# CY8C5888LTI_LP097 register map
File version: 0.1
Registers are 8-bit, read-write, no defined reset value unless marked. A register's access mark holds for its fields unless they carry their own. Offsets are from the block's base; [hi:lo] are bit positions; 'fields as' and 'values as' point back to an identical list.

## RC_Ch1_Timer
Base 0x00000000
0x40006408 RC_Ch1_Timer_COUNTER 24-bit — UDB.A0 - Current Down Counter Value
0x40006428 RC_Ch1_Timer_PERIOD 24-bit — UDB.D0 - Assigned Period
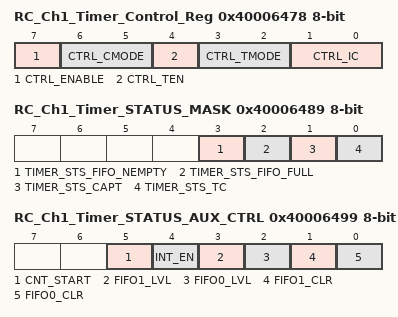
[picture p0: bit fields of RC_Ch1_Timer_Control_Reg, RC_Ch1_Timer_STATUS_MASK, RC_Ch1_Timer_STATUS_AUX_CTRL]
0x40006478 RC_Ch1_Timer_Control_Reg — UDB Control Register - Assigned Control Register Value
  [7] CTRL_ENABLE — Enable the Timer
  [6:5] CTRL_CMODE — Capture Mode
  [4] CTRL_TEN — Trigger Enable Bit
  [3:2] CTRL_TMODE — Trigger Mode
  [1:0] CTRL_IC — Interrupt Count
0x40006489 RC_Ch1_Timer_STATUS_MASK — UDB Status bits Interrupt Mask Enable Register
  [3] TIMER_STS_FIFO_NEMPTY ro — FIFO Empty status
  [2] TIMER_STS_FIFO_FULL ro — FIFO Full Status
  [1] TIMER_STS_CAPT ro — Enables the Interrupt on Capture
  [0] TIMER_STS_TC ro — Enables the Interrupt on TC
0x40006499 RC_Ch1_Timer_STATUS_AUX_CTRL — UDB Auxilliary Control Register
  [5] CNT_START — FIFO0 clear
    0=E_CNT_START0 (Disable counter); 1=E_CNT_START1 (Enable counter)
  [4] INT_EN
    0=E_INT_EN0 (Interrupt disabled); 1=E_INT_EN1 (Interrupt enabled)
  [3] FIFO1_LVL — FIFO level
    0=E_FIFO_LVL_0 (FIFO LVL: input mode: FIFO not full; output mode: FIFO not empty); 1=E_FIFO_LVL_1 (FIFO LVL: input mode: FIFO at least 1/2 empty; output mode: FIFO at least 1/2 full)
  [2] FIFO0_LVL — FIFO level
    values as FIFO1_LVL
  [1] FIFO1_CLR — FIFO1 clear
    0=E_FIFO_CLR_0 (Normal FIFO operation); 1=E_FIFO_CLR_1 (Clear FIFO state)
  [0] FIFO0_CLR — FIFO0 clear
    values as FIFO1_CLR

## Drive_DC_Motor_PWM
Base 0x00000000
0x4000652A Drive_DC_Motor_PWM__COMPARE1 — UDB.D0 - Assigned Compare1 Value
0x4000653A Drive_DC_Motor_PWM__COMPARE2 — UDB.D1 - Assigned Compare2 Value
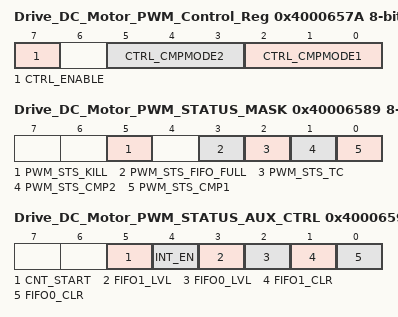
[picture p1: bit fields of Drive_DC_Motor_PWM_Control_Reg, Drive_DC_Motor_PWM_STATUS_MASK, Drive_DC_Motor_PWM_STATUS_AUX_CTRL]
0x4000657A Drive_DC_Motor_PWM_Control_Reg — UDB Control Register - Assigned Control Register Value
  [7] CTRL_ENABLE — Enable the PWM
  [5:3] CTRL_CMPMODE2 — Compare mode 2
  [2:0] CTRL_CMPMODE1 — Compare mode 1
0x40006589 Drive_DC_Motor_PWM_STATUS_MASK — UDB Status bits Interrupt Mask Enable Register
  [5] PWM_STS_KILL ro — Enables the Interrupt on Kill
  [3] PWM_STS_FIFO_FULL ro — FIFO Full Status Mask
  [2] PWM_STS_TC ro — Enables the Interrupt on Terminal Count
  [1] PWM_STS_CMP2 ro — Enables the Interrupt on Compare 2
  [0] PWM_STS_CMP1 ro — Enables the Interrupt on Compare 1
0x4000659A Drive_DC_Motor_PWM_STATUS_AUX_CTRL — UDB Auxilliary Control Register
  [5] CNT_START — FIFO0 clear
    0=E_CNT_START0 (Disable counter); 1=E_CNT_START1 (Enable counter)
  [4] INT_EN
    0=E_INT_EN0 (Interrupt disabled); 1=E_INT_EN1 (Interrupt enabled)
  [3] FIFO1_LVL — FIFO level
    0=E_FIFO_LVL_0 (FIFO LVL: input mode: FIFO not full; output mode: FIFO not empty); 1=E_FIFO_LVL_1 (FIFO LVL: input mode: FIFO at least 1/2 empty; output mode: FIFO at least 1/2 full)
  [2] FIFO0_LVL — FIFO level
    values as FIFO1_LVL
  [1] FIFO1_CLR — FIFO1 clear
    0=E_FIFO_CLR_0 (Normal FIFO operation); 1=E_FIFO_CLR_1 (Clear FIFO state)
  [0] FIFO0_CLR — FIFO0 clear
    values as FIFO1_CLR

## RC_Ch4_Timer
Base 0x00000000
0x40006404 RC_Ch4_Timer_COUNTER 24-bit — UDB.A0 - Current Down Counter Value
0x40006424 RC_Ch4_Timer_PERIOD 24-bit — UDB.D0 - Assigned Period
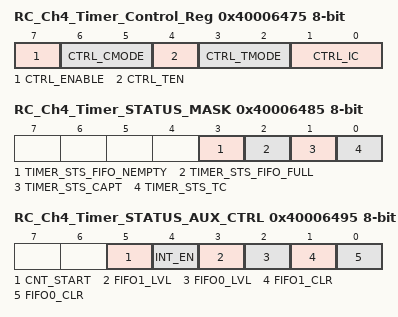
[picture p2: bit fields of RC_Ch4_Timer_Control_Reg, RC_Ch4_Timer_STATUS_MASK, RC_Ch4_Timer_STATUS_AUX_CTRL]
0x40006475 RC_Ch4_Timer_Control_Reg — UDB Control Register - Assigned Control Register Value
  [7] CTRL_ENABLE — Enable the Timer
  [6:5] CTRL_CMODE — Capture Mode
  [4] CTRL_TEN — Trigger Enable Bit
  [3:2] CTRL_TMODE — Trigger Mode
  [1:0] CTRL_IC — Interrupt Count
0x40006485 RC_Ch4_Timer_STATUS_MASK — UDB Status bits Interrupt Mask Enable Register
  [3] TIMER_STS_FIFO_NEMPTY ro — FIFO Empty status
  [2] TIMER_STS_FIFO_FULL ro — FIFO Full Status
  [1] TIMER_STS_CAPT ro — Enables the Interrupt on Capture
  [0] TIMER_STS_TC ro — Enables the Interrupt on TC
0x40006495 RC_Ch4_Timer_STATUS_AUX_CTRL — UDB Auxilliary Control Register
  [5] CNT_START — FIFO0 clear
    0=E_CNT_START0 (Disable counter); 1=E_CNT_START1 (Enable counter)
  [4] INT_EN
    0=E_INT_EN0 (Interrupt disabled); 1=E_INT_EN1 (Interrupt enabled)
  [3] FIFO1_LVL — FIFO level
    0=E_FIFO_LVL_0 (FIFO LVL: input mode: FIFO not full; output mode: FIFO not empty); 1=E_FIFO_LVL_1 (FIFO LVL: input mode: FIFO at least 1/2 empty; output mode: FIFO at least 1/2 full)
  [2] FIFO0_LVL — FIFO level
    values as FIFO1_LVL
  [1] FIFO1_CLR — FIFO1 clear
    0=E_FIFO_CLR_0 (Normal FIFO operation); 1=E_FIFO_CLR_1 (Clear FIFO state)
  [0] FIFO0_CLR — FIFO0 clear
    values as FIFO1_CLR

## RC_Ch3_Timer
Base 0x00000000
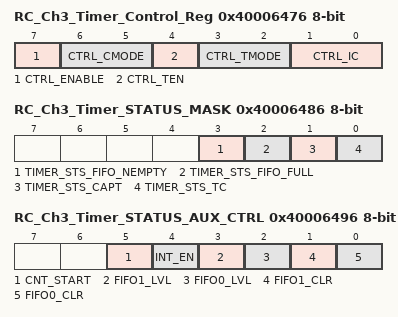
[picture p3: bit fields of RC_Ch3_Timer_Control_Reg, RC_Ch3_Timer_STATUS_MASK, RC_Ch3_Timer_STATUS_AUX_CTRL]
0x40006476 RC_Ch3_Timer_Control_Reg — UDB Control Register - Assigned Control Register Value
  [7] CTRL_ENABLE — Enable the Timer
  [6:5] CTRL_CMODE — Capture Mode
  [4] CTRL_TEN — Trigger Enable Bit
  [3:2] CTRL_TMODE — Trigger Mode
  [1:0] CTRL_IC — Interrupt Count
0x40006486 RC_Ch3_Timer_STATUS_MASK — UDB Status bits Interrupt Mask Enable Register
  [3] TIMER_STS_FIFO_NEMPTY ro — FIFO Empty status
  [2] TIMER_STS_FIFO_FULL ro — FIFO Full Status
  [1] TIMER_STS_CAPT ro — Enables the Interrupt on Capture
  [0] TIMER_STS_TC ro — Enables the Interrupt on TC
0x40006496 RC_Ch3_Timer_STATUS_AUX_CTRL — UDB Auxilliary Control Register
  [5] CNT_START — FIFO0 clear
    0=E_CNT_START0 (Disable counter); 1=E_CNT_START1 (Enable counter)
  [4] INT_EN
    0=E_INT_EN0 (Interrupt disabled); 1=E_INT_EN1 (Interrupt enabled)
  [3] FIFO1_LVL — FIFO level
    0=E_FIFO_LVL_0 (FIFO LVL: input mode: FIFO not full; output mode: FIFO not empty); 1=E_FIFO_LVL_1 (FIFO LVL: input mode: FIFO at least 1/2 empty; output mode: FIFO at least 1/2 full)
  [2] FIFO0_LVL — FIFO level
    values as FIFO1_LVL
  [1] FIFO1_CLR — FIFO1 clear
    0=E_FIFO_CLR_0 (Normal FIFO operation); 1=E_FIFO_CLR_1 (Clear FIFO state)
  [0] FIFO0_CLR — FIFO0 clear
    values as FIFO1_CLR
0x40006504 RC_Ch3_Timer_COUNTER 24-bit — UDB.A0 - Current Down Counter Value
0x40006524 RC_Ch3_Timer_PERIOD 24-bit — UDB.D0 - Assigned Period

## RC_Ch2_Timer
Base 0x00000000
0x40006400 RC_Ch2_Timer_COUNTER 24-bit — UDB.A0 - Current Down Counter Value
0x40006420 RC_Ch2_Timer_PERIOD 24-bit — UDB.D0 - Assigned Period
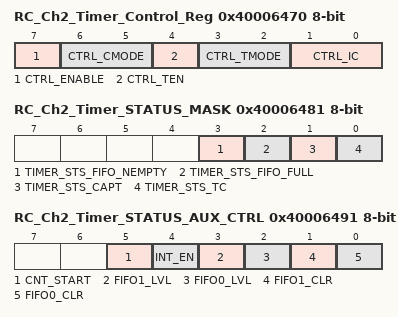
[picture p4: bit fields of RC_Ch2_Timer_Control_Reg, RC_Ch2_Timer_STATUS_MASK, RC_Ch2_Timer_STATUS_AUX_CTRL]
0x40006470 RC_Ch2_Timer_Control_Reg — UDB Control Register - Assigned Control Register Value
  [7] CTRL_ENABLE — Enable the Timer
  [6:5] CTRL_CMODE — Capture Mode
  [4] CTRL_TEN — Trigger Enable Bit
  [3:2] CTRL_TMODE — Trigger Mode
  [1:0] CTRL_IC — Interrupt Count
0x40006481 RC_Ch2_Timer_STATUS_MASK — UDB Status bits Interrupt Mask Enable Register
  [3] TIMER_STS_FIFO_NEMPTY ro — FIFO Empty status
  [2] TIMER_STS_FIFO_FULL ro — FIFO Full Status
  [1] TIMER_STS_CAPT ro — Enables the Interrupt on Capture
  [0] TIMER_STS_TC ro — Enables the Interrupt on TC
0x40006491 RC_Ch2_Timer_STATUS_AUX_CTRL — UDB Auxilliary Control Register
  [5] CNT_START — FIFO0 clear
    0=E_CNT_START0 (Disable counter); 1=E_CNT_START1 (Enable counter)
  [4] INT_EN
    0=E_INT_EN0 (Interrupt disabled); 1=E_INT_EN1 (Interrupt enabled)
  [3] FIFO1_LVL — FIFO level
    0=E_FIFO_LVL_0 (FIFO LVL: input mode: FIFO not full; output mode: FIFO not empty); 1=E_FIFO_LVL_1 (FIFO LVL: input mode: FIFO at least 1/2 empty; output mode: FIFO at least 1/2 full)
  [2] FIFO0_LVL — FIFO level
    values as FIFO1_LVL
  [1] FIFO1_CLR — FIFO1 clear
    0=E_FIFO_CLR_0 (Normal FIFO operation); 1=E_FIFO_CLR_1 (Clear FIFO state)
  [0] FIFO0_CLR — FIFO0 clear
    values as FIFO1_CLR
